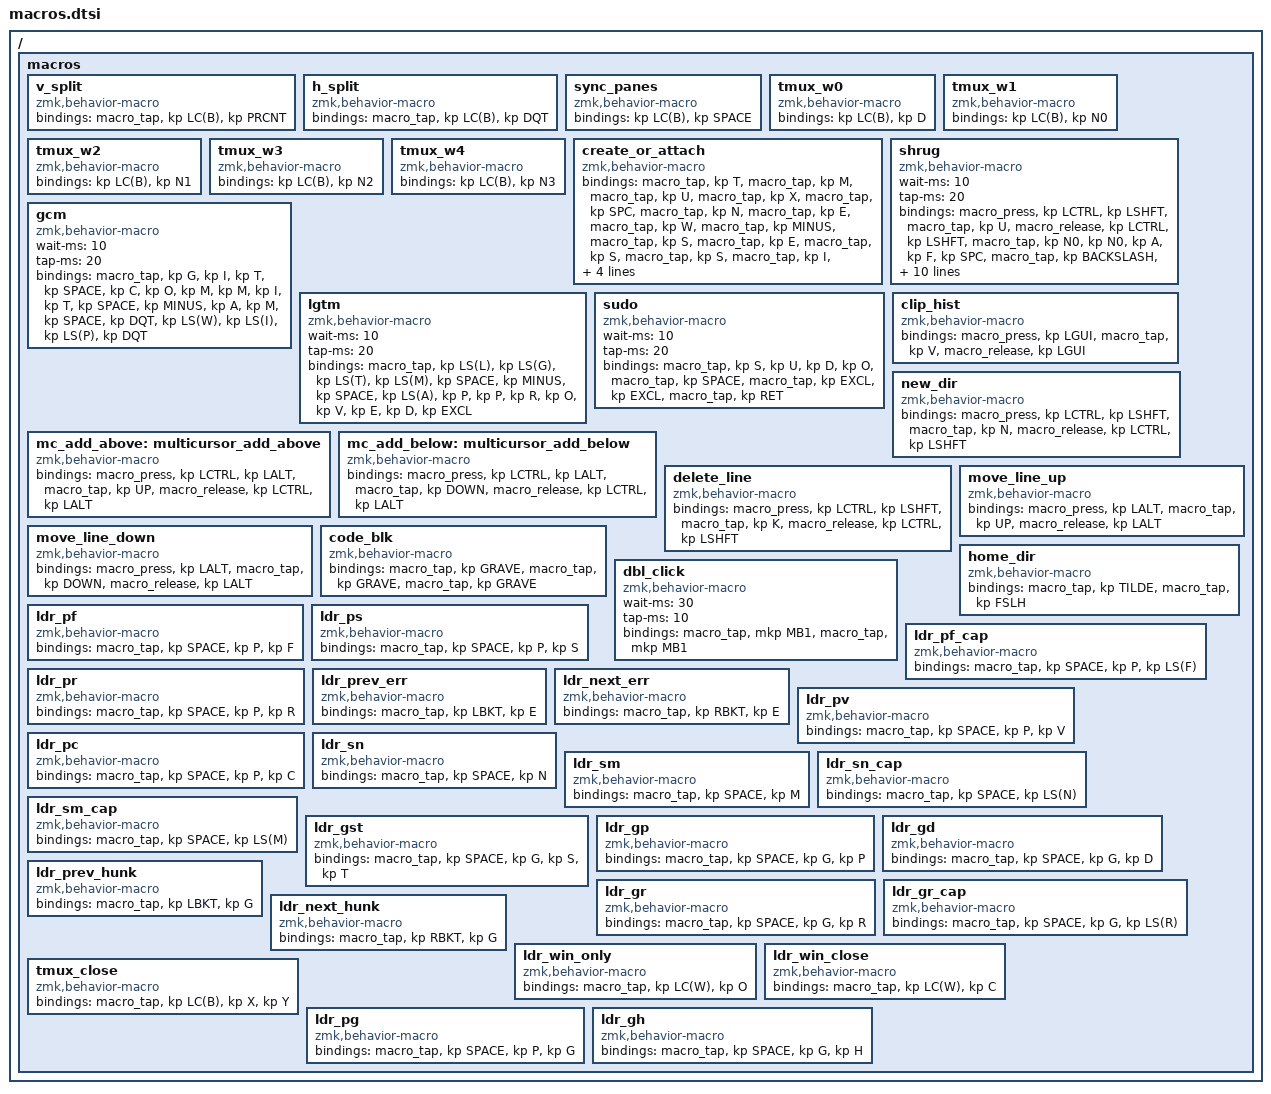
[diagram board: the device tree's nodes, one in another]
/ {
    macros {
        v_split: v_split {
            compatible = "zmk,behavior-macro";
            #binding-cells = <0>;
            bindings = <&macro_tap &kp LC(B) &kp PRCNT>;
        };

        h_split: h_split {
            compatible = "zmk,behavior-macro";
            #binding-cells = <0>;
            bindings = <&macro_tap &kp LC(B) &kp DQT>;
        };

        sync_panes: sync_panes {
            compatible = "zmk,behavior-macro";
            #binding-cells = <0>;
            bindings = <&kp LC(B) &kp SPACE>;
        };

        tmux_w0: tmux_w0 { // tmux detach
            compatible = "zmk,behavior-macro";
            #binding-cells = <0>;
            bindings = <&kp LC(B) &kp D>;
        };

        tmux_w1: tmux_w1 { // tmux window 0
            compatible = "zmk,behavior-macro";
            #binding-cells = <0>;
            bindings = <&kp LC(B) &kp N0>;
        };

        tmux_w2: tmux_w2 { // tmux window 1
            compatible = "zmk,behavior-macro";
            #binding-cells = <0>;
            bindings = <&kp LC(B) &kp N1>;
        };

        tmux_w3: tmux_w3 { // tmux window 2
            compatible = "zmk,behavior-macro";
            #binding-cells = <0>;
            bindings = <&kp LC(B) &kp N2>;
        };

        tmux_w4: tmux_w4 { // tmux window 3
            compatible = "zmk,behavior-macro";
            #binding-cells = <0>;
            bindings = <&kp LC(B) &kp N3>;
        };

        create_or_attach: create_or_attach {
            compatible = "zmk,behavior-macro";
            #binding-cells = <0>;
            bindings
                = <&macro_tap &kp T>
                , <&macro_tap &kp M>
                , <&macro_tap &kp U>
                , <&macro_tap &kp X>
                , <&macro_tap &kp SPC>
                , <&macro_tap &kp N>
                , <&macro_tap &kp E>
                , <&macro_tap &kp W>
                , <&macro_tap &kp MINUS>
                , <&macro_tap &kp S>
                , <&macro_tap &kp E>
                , <&macro_tap &kp S>
                , <&macro_tap &kp S>
                , <&macro_tap &kp I>
                , <&macro_tap &kp O>
                , <&macro_tap &kp N>
                , <&macro_tap &kp SPC>
                , <&macro_tap &kp MINUS>
                , <&macro_tap &kp A>
                , <&macro_tap &kp SPC>
                , <&macro_tap &kp MINUS>
                , <&macro_tap &kp S>
                , <&macro_tap &kp SPC>
            ;
        };

        shrug: shrug { // shrug emoji ¯\_(ツ)_/¯
            compatible = "zmk,behavior-macro";
            #binding-cells = <0>;
            wait-ms = <10>;
            tap-ms = <20>;
            bindings
                // ¯ (Macros)
                = <&macro_press &kp LCTRL &kp LSHFT>
                , <&macro_tap &kp U>
                , <&macro_release &kp LCTRL &kp LSHFT>
                , <&macro_tap &kp N0 &kp N0 &kp A &kp F &kp SPC>
                // \
                , <&macro_tap &kp BACKSLASH>
                , <&macro_tap &kp BACKSLASH>
                // _
                , <&macro_tap &kp UNDER>
                // (
                , <&macro_tap &kp LPAR>
                // ツ (Katakana Letter Tu)
                , <&macro_press &kp LCTRL &kp LSHFT>
                , <&macro_tap &kp U>
                , <&macro_release &kp LCTRL &kp LSHFT>
                , <&macro_tap &kp N3 &kp N0 &kp C &kp N4 &kp SPC>
                // )
                , <&macro_tap &kp RPAR>
                // _
                , <&macro_tap &kp UNDER>
                // /
                , <&macro_tap &kp FSLH>
                // ¯ (Macron)
                , <&macro_press &kp LCTRL &kp LSHFT>
                , <&macro_tap &kp U>
                , <&macro_release &kp LCTRL &kp LSHFT>
                , <&macro_tap &kp N0 &kp N0 &kp A &kp F &kp SPC>
                ;
        };

        gcm: gcm { // git commit WIP
            compatible = "zmk,behavior-macro";
            #binding-cells = <0>;
            wait-ms = <10>;
            tap-ms = <20>;
            bindings = <
                &macro_tap &kp G &kp I &kp T &kp SPACE
                &kp C &kp O &kp M &kp M &kp I &kp T &kp SPACE
                &kp MINUS &kp A &kp M &kp SPACE
                &kp DQT &kp LS(W) &kp LS(I) &kp LS(P) &kp DQT
            >;
        };

        lgtm: lgtm { // LGTM Approval
            compatible = "zmk,behavior-macro";
            #binding-cells = <0>;
            wait-ms = <10>;
            tap-ms = <20>;
            bindings = <
                &macro_tap
                &kp LS(L) &kp LS(G) &kp LS(T) &kp LS(M)
                &kp SPACE &kp MINUS &kp SPACE
                &kp LS(A) &kp P &kp P &kp R &kp O &kp V &kp E &kp D &kp EXCL
            >;
        };

        sudo: sudo { // SUDO_BANG_BANG
            compatible = "zmk,behavior-macro";
            #binding-cells = <0>;
            wait-ms = <10>;
            tap-ms = <20>;
            bindings
                = <&macro_tap &kp S &kp U &kp D &kp O>  // "sudo"
                , <&macro_tap &kp SPACE>                // space
                , <&macro_tap &kp EXCL &kp EXCL>        // "!!"
                , <&macro_tap &kp RET>                  // Enter key
                ;
        };
        
        clip_hist: clip_hist { // CLIPBOARD_HISTORY
            compatible = "zmk,behavior-macro";
            #binding-cells = <0>;
            bindings 
                = <&macro_press &kp LGUI>
                , <&macro_tap &kp V>
                , <&macro_release &kp LGUI>
                ;
        };
        
        new_dir: new_dir {
            compatible = "zmk,behavior-macro";
            #binding-cells = <0>;
            bindings
                = <&macro_press &kp LCTRL &kp LSHFT>
                , <&macro_tap &kp N>
                , <&macro_release &kp LCTRL &kp LSHFT>
                ;
        };

        mc_add_above: multicursor_add_above {
            compatible = "zmk,behavior-macro";
            #binding-cells = <0>;
            bindings
                = <&macro_press &kp LCTRL &kp LALT>
                , <&macro_tap &kp UP>
                , <&macro_release &kp LCTRL &kp LALT>
                ;
        };

        mc_add_below: multicursor_add_below {
            compatible = "zmk,behavior-macro";
            #binding-cells = <0>;
            bindings
                = <&macro_press &kp LCTRL &kp LALT>
                , <&macro_tap &kp DOWN>
                , <&macro_release &kp LCTRL &kp LALT>
                ;
        };

        delete_line: delete_line {
            compatible = "zmk,behavior-macro";
            #binding-cells = <0>;
            bindings
                = <&macro_press &kp LCTRL &kp LSHFT>
                , <&macro_tap &kp K>
                , <&macro_release &kp LCTRL &kp LSHFT>
                ;
        };

        move_line_up: move_line_up {
            compatible = "zmk,behavior-macro";
            #binding-cells = <0>;
            bindings
                = <&macro_press &kp LALT>
                , <&macro_tap &kp UP>
                , <&macro_release &kp LALT>
                ;
        };

        move_line_down: move_line_down {
            compatible = "zmk,behavior-macro";
            #binding-cells = <0>;
            bindings
                = <&macro_press &kp LALT>
                , <&macro_tap &kp DOWN>
                , <&macro_release &kp LALT>
                ;
        };

        code_blk: code_blk {
            compatible = "zmk,behavior-macro";
            #binding-cells = <0>;
            bindings
                = <&macro_tap &kp GRAVE>
                , <&macro_tap &kp GRAVE>
                , <&macro_tap &kp GRAVE>
                ;
        };
        
        home_dir: home_dir {
            compatible = "zmk,behavior-macro";
            #binding-cells = <0>;
            bindings
                = <&macro_tap &kp TILDE>
                , <&macro_tap &kp FSLH>
                ;
        };

        dbl_click: dbl_click {
            compatible = "zmk,behavior-macro";
            #binding-cells = <0>;
            wait-ms = <30>;
            tap-ms = <10>;
            bindings
                = <&macro_tap &mkp MB1>
                , <&macro_tap &mkp MB1>
                ;
        };

        // --- LEADER layer macros (nvim / tmux) ---

        ldr_pf: ldr_pf { // nvim: <leader>pf
            compatible = "zmk,behavior-macro";
            #binding-cells = <0>;
            bindings = <&macro_tap &kp SPACE &kp P &kp F>;
        };

        ldr_pf_cap: ldr_pf_cap { // nvim: <leader>pF
            compatible = "zmk,behavior-macro";
            #binding-cells = <0>;
            bindings = <&macro_tap &kp SPACE &kp P &kp LS(F)>;
        };

        ldr_ps: ldr_ps { // nvim: <leader>ps
            compatible = "zmk,behavior-macro";
            #binding-cells = <0>;
            bindings = <&macro_tap &kp SPACE &kp P &kp S>;
        };

        ldr_pr: ldr_pr { // nvim: <leader>pr
            compatible = "zmk,behavior-macro";
            #binding-cells = <0>;
            bindings = <&macro_tap &kp SPACE &kp P &kp R>;
        };

        ldr_prev_err: ldr_prev_err { // nvim: [e (prev diagnostic)
            compatible = "zmk,behavior-macro";
            #binding-cells = <0>;
            bindings = <&macro_tap &kp LBKT &kp E>;
        };

        ldr_next_err: ldr_next_err { // nvim: ]e (next diagnostic)
            compatible = "zmk,behavior-macro";
            #binding-cells = <0>;
            bindings = <&macro_tap &kp RBKT &kp E>;
        };

        ldr_pv: ldr_pv { // nvim: <leader>pv
            compatible = "zmk,behavior-macro";
            #binding-cells = <0>;
            bindings = <&macro_tap &kp SPACE &kp P &kp V>;
        };

        ldr_pc: ldr_pc { // nvim: <leader>pc
            compatible = "zmk,behavior-macro";
            #binding-cells = <0>;
            bindings = <&macro_tap &kp SPACE &kp P &kp C>;
        };

        ldr_sn: ldr_sn { // nvim: <leader>n
            compatible = "zmk,behavior-macro";
            #binding-cells = <0>;
            bindings = <&macro_tap &kp SPACE &kp N>;
        };

        ldr_sm: ldr_sm { // nvim: <leader>m
            compatible = "zmk,behavior-macro";
            #binding-cells = <0>;
            bindings = <&macro_tap &kp SPACE &kp M>;
        };

        ldr_sn_cap: ldr_sn_cap { // nvim: <leader>N
            compatible = "zmk,behavior-macro";
            #binding-cells = <0>;
            bindings = <&macro_tap &kp SPACE &kp LS(N)>;
        };

        ldr_sm_cap: ldr_sm_cap { // nvim: <leader>M
            compatible = "zmk,behavior-macro";
            #binding-cells = <0>;
            bindings = <&macro_tap &kp SPACE &kp LS(M)>;
        };

        ldr_gst: ldr_gst { // nvim: <leader>gst
            compatible = "zmk,behavior-macro";
            #binding-cells = <0>;
            bindings = <&macro_tap &kp SPACE &kp G &kp S &kp T>;
        };

        ldr_gp: ldr_gp { // nvim: <leader>gp
            compatible = "zmk,behavior-macro";
            #binding-cells = <0>;
            bindings = <&macro_tap &kp SPACE &kp G &kp P>;
        };

        ldr_gd: ldr_gd { // nvim: <leader>gd
            compatible = "zmk,behavior-macro";
            #binding-cells = <0>;
            bindings = <&macro_tap &kp SPACE &kp G &kp D>;
        };

        ldr_gr: ldr_gr { // nvim: <leader>gr
            compatible = "zmk,behavior-macro";
            #binding-cells = <0>;
            bindings = <&macro_tap &kp SPACE &kp G &kp R>;
        };

        ldr_gr_cap: ldr_gr_cap { // nvim: <leader>gR
            compatible = "zmk,behavior-macro";
            #binding-cells = <0>;
            bindings = <&macro_tap &kp SPACE &kp G &kp LS(R)>;
        };

        ldr_prev_hunk: ldr_prev_hunk { // nvim: [g (prev git hunk)
            compatible = "zmk,behavior-macro";
            #binding-cells = <0>;
            bindings = <&macro_tap &kp LBKT &kp G>;
        };

        ldr_next_hunk: ldr_next_hunk { // nvim: ]g (next git hunk)
            compatible = "zmk,behavior-macro";
            #binding-cells = <0>;
            bindings = <&macro_tap &kp RBKT &kp G>;
        };

        ldr_win_only: ldr_win_only { // nvim: ctrl+w, o (only window)
            compatible = "zmk,behavior-macro";
            #binding-cells = <0>;
            bindings = <&macro_tap &kp LC(W) &kp O>;
        };

        ldr_win_close: ldr_win_close { // nvim: ctrl+w, c (close window)
            compatible = "zmk,behavior-macro";
            #binding-cells = <0>;
            bindings = <&macro_tap &kp LC(W) &kp C>;
        };

        tmux_close: tmux_close { // tmux: ctrl+b, x, y (close pane)
            compatible = "zmk,behavior-macro";
            #binding-cells = <0>;
            bindings = <&macro_tap &kp LC(B) &kp X &kp Y>;
        };

        ldr_pg: ldr_pg { // nvim: <leader>pg
            compatible = "zmk,behavior-macro";
            #binding-cells = <0>;
            bindings = <&macro_tap &kp SPACE &kp P &kp G>;
        };

        ldr_gh: ldr_gh { // nvim: <leader>gh
            compatible = "zmk,behavior-macro";
            #binding-cells = <0>;
            bindings = <&macro_tap &kp SPACE &kp G &kp H>;
        };
    };
};
